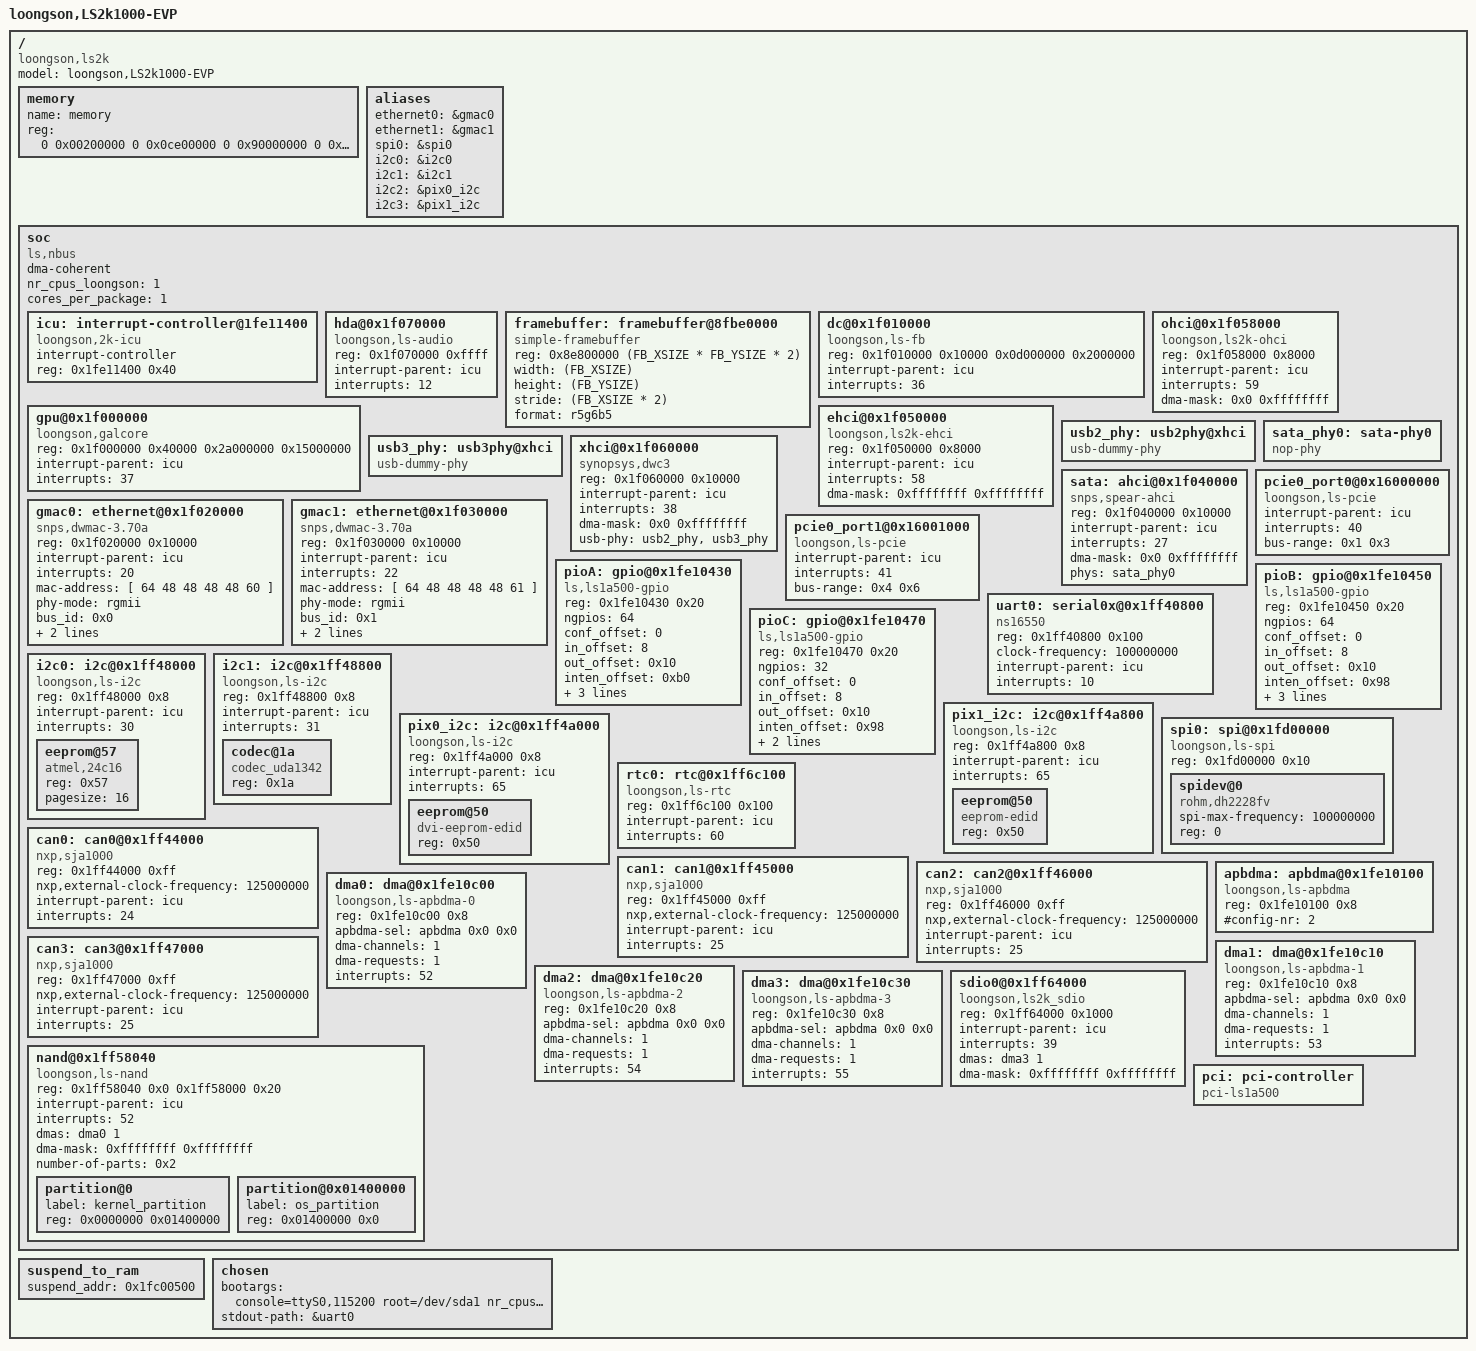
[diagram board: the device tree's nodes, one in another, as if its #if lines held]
/*
 * 2K1000 Device Tree Source for LS2K1000 boards
 */
#include <configs/ls1a500.h>
/dts-v1/;
/ {
	model = "loongson,LS2k1000-EVP";
	compatible = "loongson,ls2k";
	#address-cells = <2>;
	#size-cells = <2>;

	// Since 2K1000 support > 4GiB DIMM, use 2 cell for and address size
	memory {
		name = "memory";
		device_type = "memory";
#ifdef NOGPU
		reg =  <0 0x00200000 0 0x0ce00000	// 200MiB at 2MiB
#else
		reg =  <0 0x00200000 0 0x0ee00000	// 200MiB at 2MiB
#endif
			0 0x90000000 0 0x70000000	// 2GB - 256MB
			>;
	};
	aliases {
		ethernet0 = &gmac0;
		ethernet1 = &gmac1;
		spi0 = &spi0;
		i2c0 = &i2c0;
                i2c1 = &i2c1;
                i2c2 = &pix0_i2c;
                i2c3 = &pix1_i2c;
	};

	// all soc device use 32bit address

	soc {
		compatible = "ls,nbus", "simple-bus";
		#address-cells = <1>;
		#size-cells = <1>;
		ranges = <0x10000000 0 0x10000000 0x10000000
			  0x40000000 0 0x40000000 0x40000000
			  0x20000000 0 0x20000000 0x20000000
              0x0d000000 0 0x0d000000 0x02000000>;

		dma-coherent;
		nr_cpus_loongson = <1>;
		cores_per_package = <1>;

		icu: interrupt-controller@1fe11400 {
			compatible = "loongson,2k-icu";
			interrupt-controller;
			#interrupt-cells = <1>;
			reg = <0x1fe11400 0x40>;
		};
/*
		msi: pci-msi-controller@1fe114a0 {
			compatible = "loongson,2k-pci-msi";
			msi-controller;
			interrupt-parent = <&icu>;
			msi-mask = <0x000000c0 0x40000c00>;
			reg = <0x1fe114a0 0x60>;
		};
*/
		/* HDA controller nodes:
		 * If you want to use the "hda" function,enable the "hda"
		 * controller by configure general configuration register 0.
		 */
		hda@0x1f070000 {
			compatible = "loongson,ls-audio";
			reg = <0x1f070000 0xffff>;
			interrupt-parent = <&icu>;
			interrupts = <12>;
		};

		framebuffer: framebuffer@8fbe0000 {
		//	display = <&lcdscreen0>;
			compatible = "simple-framebuffer";
			status = "okay";
			reg = <0x8e800000 (FB_XSIZE * FB_YSIZE * 2)>;
			width = < (FB_XSIZE) >;
			height = < (FB_YSIZE) >;
			stride = <(FB_XSIZE * 2)>;
			format = "r5g6b5";
		};
#if 1
		dc@0x1f010000 {
			compatible = "loongson,ls-fb";
			reg = <0x1f010000 0x10000
#ifdef NOGPU
				   0x0d000000 0x2000000>;
#else
				   0x20000000 0x8000000>;
#endif
			interrupt-parent = <&icu>;
			interrupts = <36>;
		};
#ifndef NOGPU
		gpu@0x1f000000 {
			compatible = "loongson,galcore";
			reg = <0x1f000000 0x40000
				0x2a000000 0x15000000>;
			interrupt-parent = <&icu>;
			interrupts = <37>;
		};
#endif
		ohci@0x1f058000 {
			compatible = "loongson,ls2k-ohci", "usb-ohci", "generic-ohci";
			reg = <0x1f058000 0x8000>;
			interrupt-parent = <&icu>;
			interrupts = <59>;
			dma-mask = <0x0 0xffffffff>;
		};

		ehci@0x1f050000 {
			compatible = "loongson,ls2k-ehci", "usb-ehci", "generic-ehci";
			reg = <0x1f050000 0x8000>;
			interrupt-parent = <&icu>;
			interrupts = <58>;
			dma-mask = <0xffffffff 0xffffffff>;
		};

		usb2_phy: usb2phy@xhci {
			compatible = "usb-dummy-phy";
		};

		usb3_phy: usb3phy@xhci {
			compatible = "usb-dummy-phy";
		};

		xhci@0x1f060000 {
			compatible = "synopsys,dwc3", "snps,dwc3";
			reg = <0x1f060000 0x10000>;
			interrupt-parent = <&icu>;
			interrupts = <38>;
			dma-mask = <0x0 0xffffffff>;
			usb-phy = <&usb2_phy>, <&usb3_phy>;
		};

#if 0
		otg@0x1f080000 {
			compatible = "loongson,dwc-otg", "dwc-otg", "snps,dwc2";
			reg = <0x1f080000 0x40000>;
			interrupt-parent = <&icu>;
			interrupts = <57>;
			dma-mask = <0x0 0xffffffff>;
		};
#endif

		sata_phy0: sata-phy0 {
			compatible = "nop-phy";
			#phy-cells = <0>;
		};

		sata: ahci@0x1f040000{
			compatible = "snps,spear-ahci";
			reg = <0x1f040000 0x10000>;
			interrupt-parent = <&icu>;
			interrupts = <27>;
			dma-mask = <0x0 0xffffffff>;
			phys = <&sata_phy0>;
			phy-names = "sata-phy";
		};

		gmac0: ethernet@0x1f020000 {
			compatible = "snps,dwmac-3.70a", "ls,ls-gmac", "loongson,ls1a-gmac" ;
			reg = <0x1f020000 0x10000>;
			interrupt-parent = <&icu>;
			interrupts = <20>;
			interrupt-names = "macirq";
			mac-address = [ 64 48 48 48 48 60 ];/* [>mac 64:48:48:48:48:60 <]*/
			phy-mode = "rgmii";
			bus_id = <0x0>;
			phy_addr = <0xffffffff>;
			dma-mask = <0xffffffff 0xffffffff>;
		};

		gmac1: ethernet@0x1f030000 {
			compatible = "snps,dwmac-3.70a", "ls,ls-gmac", "loongson,ls1a-gmac";
			reg = <0x1f030000 0x10000>;
			interrupt-parent = <&icu>;
			interrupts = <22>;
			interrupt-names = "macirq";
			mac-address = [ 64 48 48 48 48 61 ];/* [>mac 64:48:48:48:48:61 <]*/
			phy-mode = "rgmii";
			bus_id = <0x1>;
			phy_addr = <0xffffffff>;
			dma-mask = <0xffffffff 0xffffffff>;
		};
#endif

		pcie0_port0@0x16000000 {
			compatible = "loongson,ls-pcie";
			interrupt-parent = <&icu>;
			interrupts = <40>;
			#address-cells = <3>;
			#size-cells = <2>;
			bus-range = <0x1 0x3>;
			  ranges = <0x02000000 0x0 0x40300000 0x40300000 0x0 0x8000000  //mem
				    0x01000000 0x0 0x16401000 0x16401000 0x0  0x0ff000>;  //io
		};

		pcie0_port1@0x16001000 {
			compatible = "loongson,ls-pcie";
			interrupt-parent = <&icu>;
			interrupts = <41>;
			#address-cells = <3>;
			#size-cells = <2>;
			bus-range = <0x4 0x6>;
			  ranges = <0x02000000 0x0 0x50000000 0x50000000 0x0 0x4000000  //mem
				    0x01000000 0x0 0x16500000 0x16500000 0x0  0x100000>;  //io
		};

		/*uart 2 as cpu serial*/
		uart0: serial0x@0x1ff40800{
			device_type = "serial";
			compatible = "ns16550";
			reg = <0x1ff40800 0x100>;
			/*clock-frequency = <56000000>;*/
			clock-frequency = <100000000>;
			interrupt-parent = <&icu>;
			interrupts = <10>;
		};

		pioA:gpio@0x1fe10430{
			compatible = "ls,ls1a500-gpio";
			reg = <0x1fe10430 0x20>;
			ngpios = <64>;
                        conf_offset = <0>;
			in_offset = <8>;
			out_offset = <0x10>;
			inten_offset = <0xb0>;
			gpio_base = <0>;
			irq_base = <66>;
			gpio-controller;
			#gpio-cells = <2>;
		};

		pioB:gpio@0x1fe10450{
			compatible = "ls,ls1a500-gpio";
			reg = <0x1fe10450 0x20>;
			ngpios = <64>;
                        conf_offset = <0>;
			in_offset = <8>;
			out_offset = <0x10>;
			inten_offset = <0x98>;
			gpio_base = <64>;
			irq_base = <68>;
			gpio-controller;
			#gpio-cells = <2>;
		};

		pioC:gpio@0x1fe10470{
			compatible = "ls,ls1a500-gpio";
			reg = <0x1fe10470 0x20>;
			ngpios = <32>;
                        conf_offset = <0>;
			in_offset = <8>;
			out_offset = <0x10>;
			inten_offset = <0x98>;
			gpio_base = <128>;
			gpio-controller;
			#gpio-cells = <2>;
		};

		i2c0: i2c@0x1ff48000{
			compatible = "loongson,ls-i2c";
			reg = <0x1ff48000 0x8>;
			interrupt-parent = <&icu>;
			interrupts = <30>;
			#address-cells = <1>;
			#size-cells = <0>;
			eeprom@57{
				compatible = "atmel,24c16";
				reg = <0x57>;
				pagesize = <16>;
			};
		};
		i2c1: i2c@0x1ff48800{
			#address-cells = <1>;
			#size-cells = <0>;

			compatible = "loongson,ls-i2c";
			reg = <0x1ff48800 0x8>;
			interrupt-parent = <&icu>;
			interrupts = <31>;
			codec@1a{
				compatible = "codec_uda1342";
				reg = <0x1a>;
			};

		};
		pix1_i2c: i2c@0x1ff4a800{	/* i2c5 for VGA, should be probed before pix0 */
			#address-cells = <1>;
			#size-cells = <0>;

			compatible = "loongson,ls-i2c";
			reg = <0x1ff4a800 0x8>;
			interrupt-parent = <&icu>;
			interrupts = <65>;
			eeprom@50{
				compatible = "eeprom-edid";
				reg = <0x50>;
			};

		};
		pix0_i2c: i2c@0x1ff4a000{	/* i2c4 for DVI */
			#address-cells = <1>;
			#size-cells = <0>;

			compatible = "loongson,ls-i2c";
			reg = <0x1ff4a000 0x8>;
			interrupt-parent = <&icu>;
			interrupts = <65>;
			eeprom@50{
				compatible = "dvi-eeprom-edid";
				reg = <0x50>;
			};

		};
		spi0: spi@0x1fd00000{
			compatible = "loongson,ls-spi";
			#address-cells = <1>;
			#size-cells = <0>;
			reg = <0x1fd00000 0x10>;
			spidev@0{
				compatible = "rohm,dh2228fv";
				spi-max-frequency = <100000000>;
				reg = <0>;
			};
		};
		rtc0: rtc@0x1ff6c100{
			compatible = "loongson,ls-rtc";
			reg = <0x1ff6c100 0x100>;
			interrupt-parent = <&icu>;
			interrupts = <60>;
		};

		/* CAN controller nodes:
		 * If you want to use the "can" function,enable the "can"
		 * controller by configure general configuration register 0.
		 */
		can0: can0@0x1ff44000{
			compatible = "nxp,sja1000";
			reg = <0x1ff44000 0xff>;
			nxp,external-clock-frequency = <125000000>;
			interrupt-parent = <&icu>;
			interrupts = <24>;
		};
		can1: can1@0x1ff45000{
			compatible = "nxp,sja1000";
			reg = <0x1ff45000 0xff>;
			nxp,external-clock-frequency = <125000000>;
			interrupt-parent = <&icu>;
			interrupts = <25>;
		};
		can2: can2@0x1ff46000{
			compatible = "nxp,sja1000";
			reg = <0x1ff46000 0xff>;
			nxp,external-clock-frequency = <125000000>;
			interrupt-parent = <&icu>;
			interrupts = <25>;
		};
		can3: can3@0x1ff47000{
			compatible = "nxp,sja1000";
			reg = <0x1ff47000 0xff>;
			nxp,external-clock-frequency = <125000000>;
			interrupt-parent = <&icu>;
			interrupts = <25>;
		};
#if 0
		pwm0: pwm@1ff5c000{
			compatible = "loongson,ls2k-pwm";
			reg = <0x1ff5c000 0x10>;
			interrupt-parent = <&icu>;
			interrupts = <32>;
		};
		pwm1: pwm@1ff5c010{
			compatible = "loongson,ls2k-pwm";
			reg = <0x1ff5c010 0x10>;
			interrupt-parent = <&icu>;
			interrupts = <32>;
		};
		pwm2: pwm@1ff5c020{
			compatible = "loongson,ls2k-pwm";
			reg = <0x1ff5c020 0x10>;
			interrupt-parent = <&icu>;
			interrupts = <32>;
		};
		pwm3: pwm@1ff5c030{
			compatible = "loongson,ls2k-pwm";
			reg = <0x1ff5c030 0x10>;
			interrupt-parent = <&icu>;
			interrupts = <32>;
		};
		pwm4: pwm@1ff5c040{
			compatible = "loongson,ls2k-pwm";
			reg = <0x1ff5c040 0x10>;
			interrupt-parent = <&icu>;
			interrupts = <33>;
		};
		pwm5: pwm@1ff5c050{
			compatible = "loongson,ls2k-pwm";
			reg = <0x1ff5c050 0x10>;
			interrupt-parent = <&icu>;
			interrupts = <33>;
		};
		pwm6: pwm@1ff5c060{
			compatible = "loongson,ls2k-pwm";
			reg = <0x1ff5c060 0x10>;
			interrupt-parent = <&icu>;
			interrupts = <33>;
		};
		pwm7: pwm@1ff5c070{
			compatible = "loongson,ls2k-pwm";
			reg = <0x1ff5c070 0x10>;
			interrupt-parent = <&icu>;
			interrupts = <33>;
		};
#endif
#if 1
		/* APB DMA controller nodes:
		 * apbdma node specify the commom property for dma node.
		 * the #config-nr must be 2,Used to provide APB sel region
		 * and APB DMA controler information.
		 */
		apbdma: apbdma@0x1fe10100{
			compatible = "loongson,ls-apbdma";
			reg = <0x1fe10100 0x8>;		/* bit14~15 for sdio1 dma sel */
			#config-nr = <2>;
		};
		/* DMA node should specify the apbdma-sel property using a
		 * phandle to the controller followed by number of APB sel
		 * region(max 9) and number of APB DMA controller(max 4).
		*/
		dma0: dma@0x1fe10c00 {
			compatible = "loongson,ls-apbdma-0";
			reg = <0x1fe10c00 0x8>;
			apbdma-sel = <&apbdma 0x0 0x0>;
			#dma-cells = <1>;
			dma-channels = <1>;
			dma-requests = <1>;
			interrupts = <52>;
		};
		dma1: dma@0x1fe10c10 {
			compatible = "loongson,ls-apbdma-1";
			reg = <0x1fe10c10 0x8>;
			apbdma-sel = <&apbdma 0x0 0x0>;
			#dma-cells = <1>;
			dma-channels = <1>;
			dma-requests = <1>;
			interrupts = <53>;
		};
		dma2: dma@0x1fe10c20 {
			compatible = "loongson,ls-apbdma-2";
			reg = <0x1fe10c20 0x8>;
			apbdma-sel = <&apbdma 0x0 0x0>;
			#dma-cells = <1>;
			dma-channels = <1>;
			dma-requests = <1>;
			interrupts = <54>;
		};
		dma3: dma@0x1fe10c30 {
			compatible = "loongson,ls-apbdma-3";
			reg = <0x1fe10c30 0x8>;
			apbdma-sel = <&apbdma 0x0 0x0>;
			#dma-cells = <1>;
			dma-channels = <1>;
			dma-requests = <1>;
			interrupts = <55>;
		};
		sdio0@0x1ff64000 {
			#address-cells = <1>;
			#size-cells = <1>;

			compatible = "loongson,ls2k_sdio";
			reg = <0x1ff64000 0x1000>;
			interrupt-parent = <&icu>;
			interrupts = <39>;
			interrupt-names = "ls2k_mci_irq";

			dmas = <&dma3 1>;
			dma-names = "sdio_rw";
			dma-mask = <0xffffffff 0xffffffff>;
		};
#if 0
		/* sdio1 use dma1 */
		dma_sdio1 {
			compatible = "loongson,ls-apbdma-4";
			reg = <0x1fe10c10 0x8>;
			apbdma-sel = <&apbdma 0x0 0x2>;
			#dma-cells = <1>;
			dma-channels = <1>;
			dma-requests = <1>;
			interrupts = <53>;
		};
		sdio1@0x1ff66000 {
			#address-cells = <1>;
			#size-cells = <1>;

			compatible = "loongson,ls2k_sdio";
			reg = <0x1ff66000 0x1000>;
			interrupt-parent = <&icu>;
			interrupts = <39>;
			interrupt-names = "ls2k_mci_irq";

			#dmas = <&dma_sdio1 1>;	//todo: write cfg0 to select dma
			dma-names = "sdio_rw";
			dma-mask = <0xffffffff 0xffffffff>;
		};
#endif
#endif
#if 0
		i2s: i2s@0x1ff54000 {
			compatible = "loongson,ls-i2s";
			reg = <0x1ff54000 0x10>;
		};
		audio: audio@0x1ff54000 {
			compatible = "loongson,ls-pcm-audio";
			reg = <0x1ff54000 0x10>;
			interrupt-parent = <&icu>;
			interrupts = <54 55>;
			interrupt-names = "i2s_irq0", "i2s_irq1";

			dmas = <&dma1 1
			        &dma2 1>;
			dma-names = "i2s_play", "i2s_record";
			dma-mask = <0xffffffff 0xffffffff>;
		};
		sound {
			compatible = "loongson,ls-sound";
			loongson,i2s-controller = <&i2s>;
			loongson,audio-codec = <&audio>;
		};
#endif
#if 1
		nand@0x1ff58040{
			#address-cells = <1>;
			#size-cells = <1>;
			compatible = "loongson,ls-nand";
			reg = <0x1ff58040 0x0
				0x1ff58000 0x20>;
			interrupt-parent = <&icu>;
			interrupts = <52>;
			interrupt-names = "nand_irq";

			dmas = <&dma0 1>;
			dma-names = "nand_rw";
			dma-mask = <0xffffffff 0xffffffff>;

			number-of-parts = <0x2>;

			partition@0 {
				label = "kernel_partition";
				reg = <0x0000000 0x01400000>;
			};

			partition@0x01400000 {
				label = "os_partition";
				reg = <0x01400000 0x0>;
			};
		};
#endif
#if 0
		hwmon@0x1fe07000{
			#address-cells = <1>;
			#size-cells = <1>;

			compatible = "loongson,ls-hwmon";
			reg = <0x1fe07000 0x1>;
			max-id = <0>;
			id = <0>;
		};
#endif
		pci: pci-controller {
			compatible = "pci-ls1a500";
			device_type = "pci";
			#address-cells = <3>;
			#size-cells = <2>;
			  ranges = <0x02000000 0x0 0x40100000 0x40100000 0x0 0x30000000  //mem
						0x01000000 0x0 0x18001000 0x18001000 0x0 0x5ff000>;  //io
		};
	};

	suspend_to_ram {
		suspend_addr = <0x1fc00500>;
	};

	chosen {
		/* the redundant spaces are used for save new boot args */
		bootargs = "console=ttyS0,115200 root=/dev/sda1 nr_cpus=1 maxcpus=1                                                                                                                                                                                     ";
		stdout-path = &uart0;
	};
};
